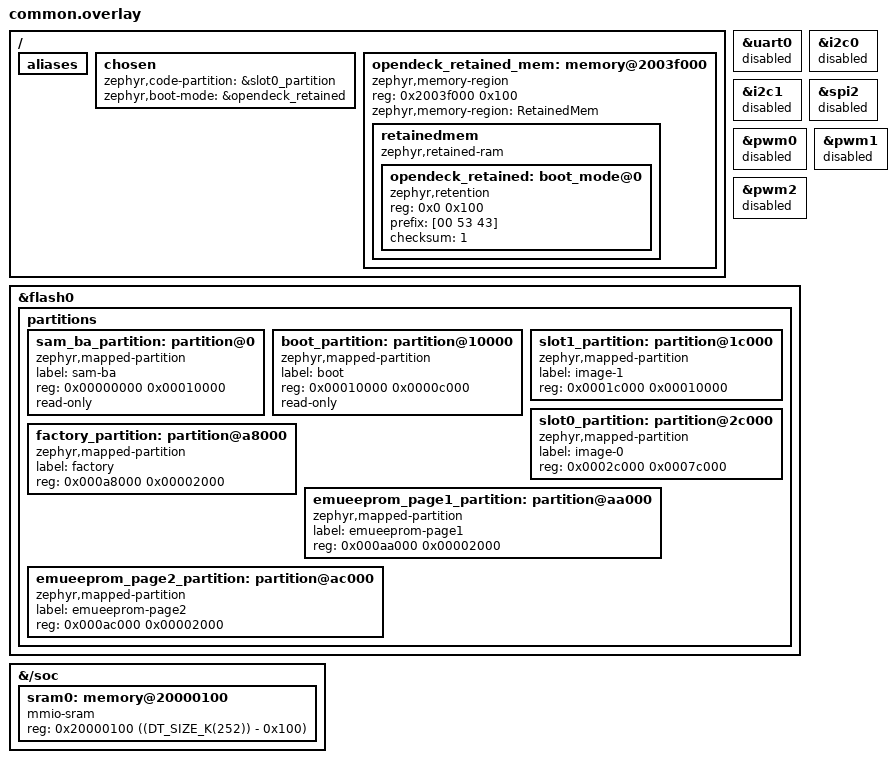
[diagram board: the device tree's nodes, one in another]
&uart0 {
    status = "disabled";
};

&i2c0 {
    status = "disabled";
};

&i2c1 {
    status = "disabled";
};

&spi2 {
    status = "disabled";
};

&pwm0 {
    status = "disabled";
};

&pwm1 {
    status = "disabled";
};

&pwm2 {
    status = "disabled";
};

/ {
    aliases {
        /delete-property/ led0;
        /delete-property/ led1;
        /delete-property/ led2;
        /delete-property/ led3;
        /delete-property/ led4;
        /delete-property/ red-pwm-led;
        /delete-property/ green-pwm-led;
        /delete-property/ blue-pwm-led;
        /delete-property/ pwm-led0;
        /delete-property/ pwm-led1;
        /delete-property/ pwm-led2;
        /delete-property/ pwm-led3;
        /delete-property/ pwm-led4;
    };

    /delete-node/ leds;
    /delete-node/ pwmleds;
    /delete-node/ pwmleds2;
};

&flash0 {
    partitions {
        ranges;
        /delete-node/ partition@0;
        /delete-node/ partition@10000;
        /delete-node/ partition@f8000;

        sam_ba_partition: partition@0 {
            compatible = "zephyr,mapped-partition";
            label = "sam-ba";
            reg = <0x00000000 0x00010000>;
            read-only;
        };

        boot_partition: partition@10000 {
            compatible = "zephyr,mapped-partition";
            label = "boot";
            reg = <0x00010000 0x0000c000>;
            read-only;
        };

        /* image-1 is the OpenDeck bootloader; keep it before image-0 so merged images stay compact. */
        slot1_partition: partition@1c000 {
            compatible = "zephyr,mapped-partition";
            label = "image-1";
            reg = <0x0001c000 0x00010000>;
        };

        slot0_partition: partition@2c000 {
            compatible = "zephyr,mapped-partition";
            label = "image-0";
            reg = <0x0002c000 0x0007c000>;
        };

        factory_partition: partition@a8000 {
            compatible = "zephyr,mapped-partition";
            label = "factory";
            reg = <0x000a8000 0x00002000>;
        };

        emueeprom_page1_partition: partition@aa000 {
            compatible = "zephyr,mapped-partition";
            label = "emueeprom-page1";
            reg = <0x000aa000 0x00002000>;
        };

        emueeprom_page2_partition: partition@ac000 {
            compatible = "zephyr,mapped-partition";
            label = "emueeprom-page2";
            reg = <0x000ac000 0x00002000>;
        };
    };
};

/delete-node/ &sram0;

&{/soc} {
    /*
     * The closed Arduino first-stage bootloader runs before OpenDeck on this
     * board. Keep OpenDeck retained RAM out of low SRAM, which it clears, and
     * leave the upper scratch area free for Arduino's reset/double-tap state.
     */
    sram0: memory@20000100 {
        compatible = "mmio-sram";
        reg = <0x20000100 ((DT_SIZE_K(252)) - 0x100)>;
        ranges = <0x0 0x20000100 ((DT_SIZE_K(252)) - 0x100)>;
        #address-cells = <1>;
        #size-cells = <1>;
    };
};

/ {
    chosen {
        zephyr,code-partition = &slot0_partition;
        zephyr,boot-mode = &opendeck_retained;
    };

    opendeck_retained_mem: memory@2003f000 {
        compatible = "zephyr,memory-region", "mmio-sram";
        reg = <0x2003f000 0x100>;
        zephyr,memory-region = "RetainedMem";
        status = "okay";

        retainedmem {
            compatible = "zephyr,retained-ram";
            status = "okay";
            #address-cells = <1>;
            #size-cells = <1>;

            opendeck_retained: boot_mode@0 {
                compatible = "zephyr,retention";
                status = "okay";
                reg = <0x0 0x100>;
                prefix = [00 53 43];
                checksum = <1>;
            };
        };
    };
};
